VERSION "pitwall.dbc 3.0 — AIM MXP SmartyCam Enhanced CAN Protocol (CANable 2.0 → Pixel 10)"

NS_ :

BS_:

BU_: DASH AIM ECU IMU GPS TPMS

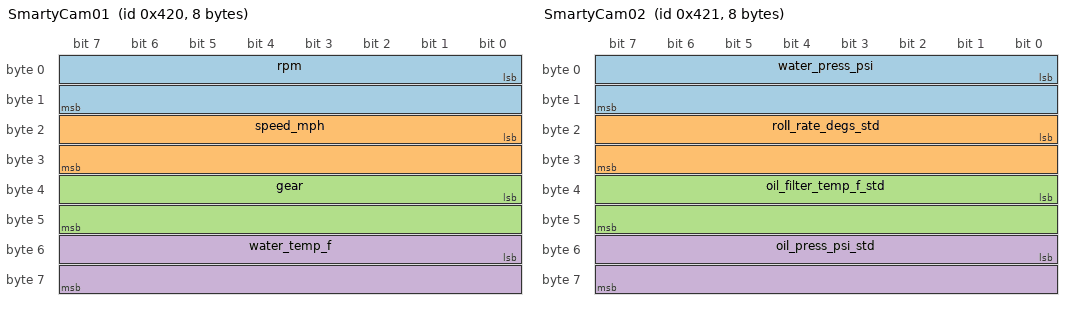
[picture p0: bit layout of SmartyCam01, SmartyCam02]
BO_ 1056 SmartyCam01: 8 AIM
 SG_ rpm : 0|16@1+ (1,0) [0|20000] "rpm" DASH
 SG_ speed_mph : 16|16@1+ (0.1,0) [0|650] "mph" DASH
 SG_ gear : 32|16@1+ (1,0) [-1|8] "gear" DASH
 SG_ water_temp_f : 48|16@1+ (0.1,0) [0|300] "F" DASH

BO_ 1057 SmartyCam02: 8 AIM
 SG_ water_press_psi : 0|16@1+ (0.1,0) [0|100] "psi" DASH
 SG_ roll_rate_degs_std : 16|16@1- (0.1,0) [-3276|3276] "deg/s" DASH
 SG_ oil_filter_temp_f_std : 32|16@1+ (0.1,0) [0|400] "F" DASH
 SG_ oil_press_psi_std : 48|16@1+ (0.1,0) [0|200] "psi" DASH

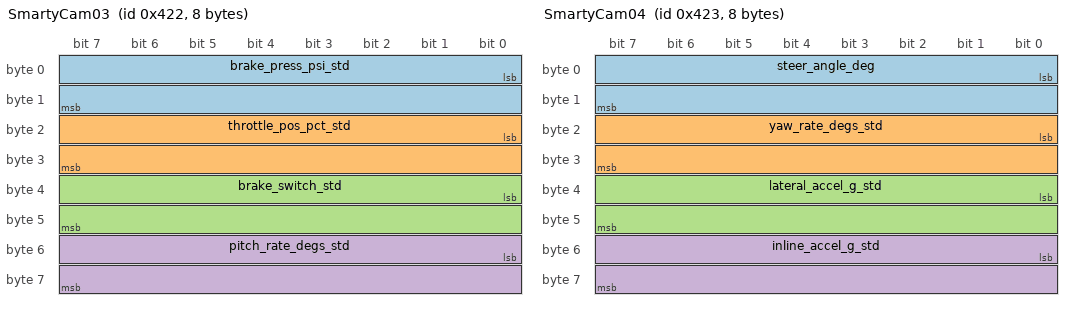
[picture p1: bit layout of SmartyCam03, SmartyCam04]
BO_ 1058 SmartyCam03: 8 AIM
 SG_ brake_press_psi_std : 0|16@1+ (1,0) [0|2000] "psi" DASH
 SG_ throttle_pos_pct_std : 16|16@1+ (0.01,0) [0|100] "%" DASH
 SG_ brake_switch_std : 32|16@1+ (1,0) [0|1] "binary" DASH
 SG_ pitch_rate_degs_std : 48|16@1- (0.1,0) [-3276|3276] "deg/s" DASH

BO_ 1059 SmartyCam04: 8 AIM
 SG_ steer_angle_deg : 0|16@1- (0.1,0) [-3276|3276] "deg" DASH
 SG_ yaw_rate_degs_std : 16|16@1- (0.1,0) [-3276|3276] "deg/s" DASH
 SG_ lateral_accel_g_std : 32|16@1- (0.01,0) [-32|32] "g" DASH
 SG_ inline_accel_g_std : 48|16@1- (0.01,0) [-32|32] "g" DASH

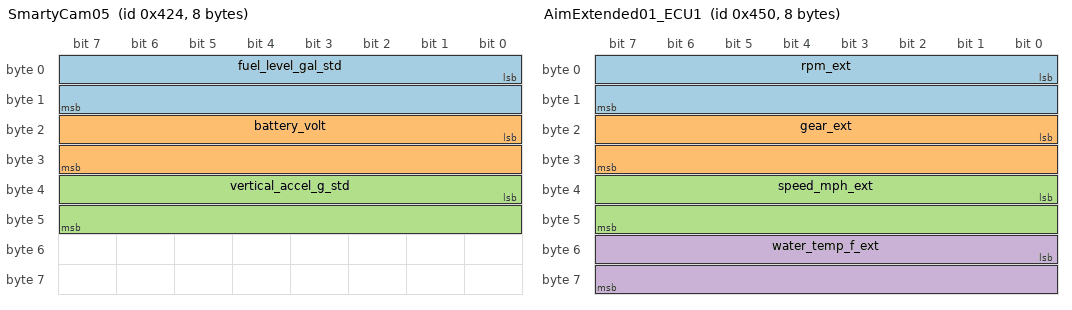
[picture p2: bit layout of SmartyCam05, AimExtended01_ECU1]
BO_ 1060 SmartyCam05: 8 AIM
 SG_ fuel_level_gal_std : 0|16@1+ (0.01,0) [0|100] "gal" DASH
 SG_ battery_volt : 16|16@1+ (0.1,0) [0|30] "V" DASH
 SG_ vertical_accel_g_std : 32|16@1- (0.01,0) [-32|32] "g" DASH

BO_ 1104 AimExtended01_ECU1: 8 AIM
 SG_ rpm_ext : 0|16@1+ (1,0) [0|20000] "rpm" DASH
 SG_ gear_ext : 16|16@1+ (1,0) [-1|8] "gear" DASH
 SG_ speed_mph_ext : 32|16@1+ (0.1,0) [0|650] "mph" DASH
 SG_ water_temp_f_ext : 48|16@1+ (0.1,0) [0|300] "F" DASH

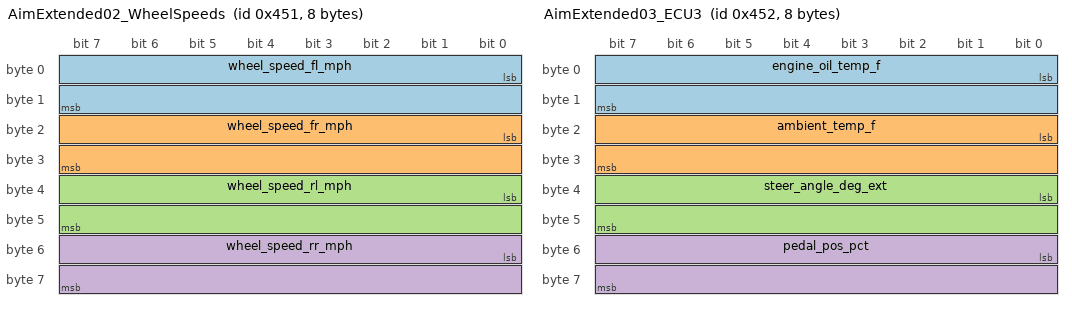
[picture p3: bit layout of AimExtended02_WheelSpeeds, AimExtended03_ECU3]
BO_ 1105 AimExtended02_WheelSpeeds: 8 AIM
 SG_ wheel_speed_fl_mph : 0|16@1+ (0.1,0) [0|650] "mph" DASH
 SG_ wheel_speed_fr_mph : 16|16@1+ (0.1,0) [0|650] "mph" DASH
 SG_ wheel_speed_rl_mph : 32|16@1+ (0.1,0) [0|650] "mph" DASH
 SG_ wheel_speed_rr_mph : 48|16@1+ (0.1,0) [0|650] "mph" DASH

BO_ 1106 AimExtended03_ECU3: 8 AIM
 SG_ engine_oil_temp_f : 0|16@1+ (0.1,0) [0|400] "F" DASH
 SG_ ambient_temp_f : 16|16@1+ (0.1,0) [-40|200] "F" DASH
 SG_ steer_angle_deg_ext : 32|16@1- (0.1,0) [-3276|3276] "deg" DASH
 SG_ pedal_pos_pct : 48|16@1+ (0.01,0) [0|100] "%" DASH

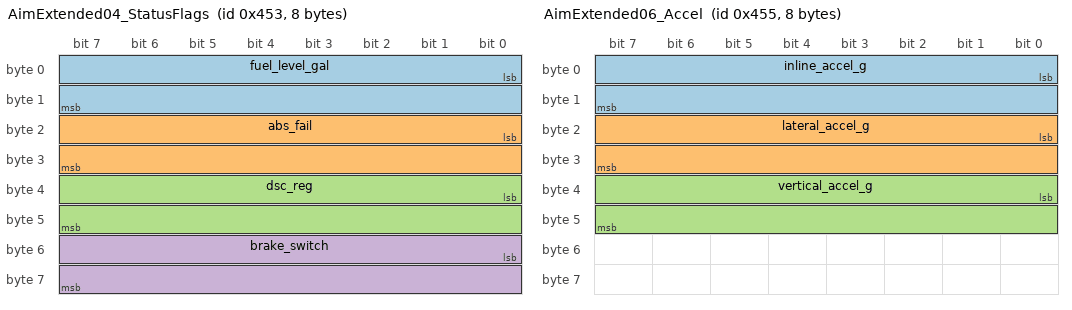
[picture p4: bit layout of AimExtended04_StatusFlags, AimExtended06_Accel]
BO_ 1107 AimExtended04_StatusFlags: 8 AIM
 SG_ fuel_level_gal : 0|16@1+ (0.01,0) [0|100] "gal" DASH
 SG_ abs_fail : 16|16@1+ (1,0) [0|1] "binary" DASH
 SG_ dsc_reg : 32|16@1+ (1,0) [0|1] "binary" DASH
 SG_ brake_switch : 48|16@1+ (1,0) [0|1] "binary" DASH

BO_ 1108 AimExtended05_MIL: 8 AIM
 SG_ mil_chk_eng : 0|16@1+ (1,0) [0|65535] "bitfield" DASH

BO_ 1109 AimExtended06_Accel: 8 AIM
 SG_ inline_accel_g : 0|16@1- (0.01,0) [-32|32] "g" DASH
 SG_ lateral_accel_g : 16|16@1- (0.01,0) [-32|32] "g" DASH
 SG_ vertical_accel_g : 32|16@1- (0.01,0) [-32|32] "g" DASH

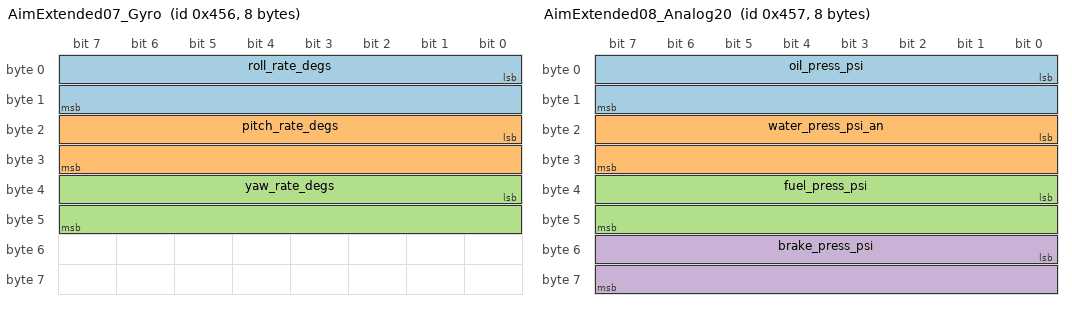
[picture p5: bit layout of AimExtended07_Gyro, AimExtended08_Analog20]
BO_ 1110 AimExtended07_Gyro: 8 AIM
 SG_ roll_rate_degs : 0|16@1- (0.1,0) [-3276|3276] "deg/s" DASH
 SG_ pitch_rate_degs : 16|16@1- (0.1,0) [-3276|3276] "deg/s" DASH
 SG_ yaw_rate_degs : 32|16@1- (0.1,0) [-3276|3276] "deg/s" DASH

BO_ 1111 AimExtended08_Analog20: 8 AIM
 SG_ oil_press_psi : 0|16@1+ (0.1,0) [0|200] "psi" DASH
 SG_ water_press_psi_an : 16|16@1+ (0.1,0) [0|100] "psi" DASH
 SG_ fuel_press_psi : 32|16@1+ (0.1,0) [0|200] "psi" DASH
 SG_ brake_press_psi : 48|16@1+ (1,0) [0|2000] "psi" DASH

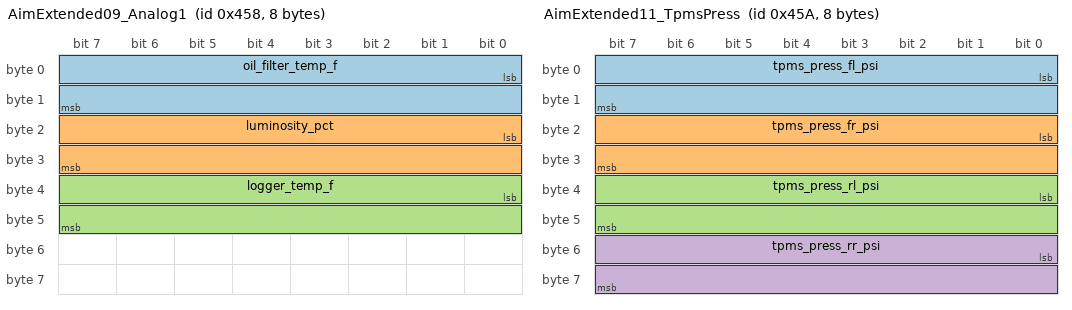
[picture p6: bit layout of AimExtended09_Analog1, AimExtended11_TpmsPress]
BO_ 1112 AimExtended09_Analog1: 8 AIM
 SG_ oil_filter_temp_f : 0|16@1+ (0.1,0) [0|400] "F" DASH
 SG_ luminosity_pct : 16|16@1+ (1,0) [0|100] "%" DASH
 SG_ logger_temp_f : 32|16@1+ (0.1,0) [-40|200] "F" DASH

BO_ 1113 AimExtended10_GPS: 8 AIM
 SG_ gps_lat : 0|32@1- (1e-7,0) [-90|90] "deg" DASH
 SG_ gps_lon : 32|32@1- (1e-7,0) [-180|180] "deg" DASH

BO_ 1114 AimExtended11_TpmsPress: 8 AIM
 SG_ tpms_press_fl_psi : 0|16@1+ (0.1,0) [0|100] "psi" DASH
 SG_ tpms_press_fr_psi : 16|16@1+ (0.1,0) [0|100] "psi" DASH
 SG_ tpms_press_rl_psi : 32|16@1+ (0.1,0) [0|100] "psi" DASH
 SG_ tpms_press_rr_psi : 48|16@1+ (0.1,0) [0|100] "psi" DASH

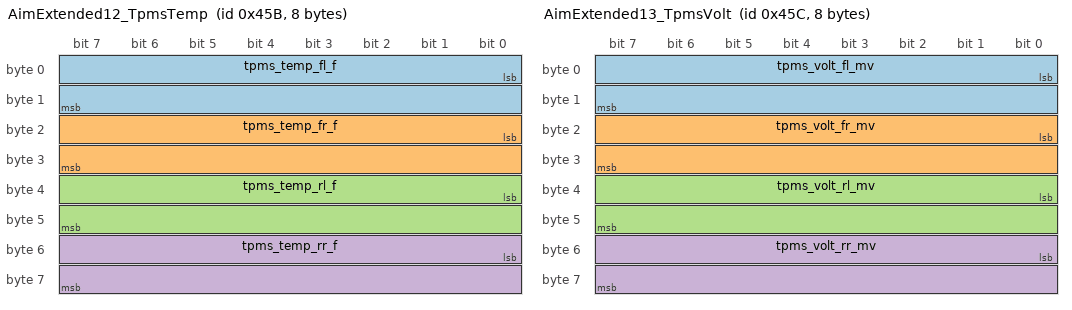
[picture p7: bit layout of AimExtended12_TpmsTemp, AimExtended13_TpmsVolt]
BO_ 1115 AimExtended12_TpmsTemp: 8 AIM
 SG_ tpms_temp_fl_f : 0|16@1+ (0.1,0) [-40|400] "F" DASH
 SG_ tpms_temp_fr_f : 16|16@1+ (0.1,0) [-40|400] "F" DASH
 SG_ tpms_temp_rl_f : 32|16@1+ (0.1,0) [-40|400] "F" DASH
 SG_ tpms_temp_rr_f : 48|16@1+ (0.1,0) [-40|400] "F" DASH

BO_ 1116 AimExtended13_TpmsVolt: 8 AIM
 SG_ tpms_volt_fl_mv : 0|16@1+ (1,0) [0|5000] "mV" DASH
 SG_ tpms_volt_fr_mv : 16|16@1+ (1,0) [0|5000] "mV" DASH
 SG_ tpms_volt_rl_mv : 32|16@1+ (1,0) [0|5000] "mV" DASH
 SG_ tpms_volt_rr_mv : 48|16@1+ (1,0) [0|5000] "mV" DASH

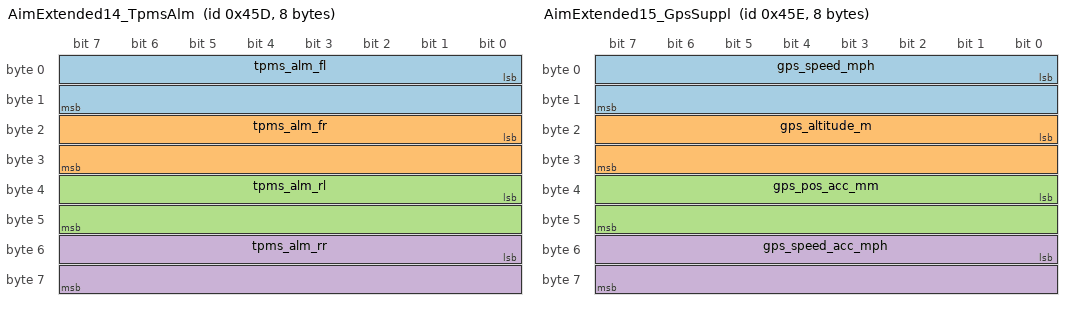
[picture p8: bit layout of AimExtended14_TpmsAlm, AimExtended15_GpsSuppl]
BO_ 1117 AimExtended14_TpmsAlm: 8 AIM
 SG_ tpms_alm_fl : 0|16@1+ (1,0) [0|65535] "bitfield" DASH
 SG_ tpms_alm_fr : 16|16@1+ (1,0) [0|65535] "bitfield" DASH
 SG_ tpms_alm_rl : 32|16@1+ (1,0) [0|65535] "bitfield" DASH
 SG_ tpms_alm_rr : 48|16@1+ (1,0) [0|65535] "bitfield" DASH

BO_ 1118 AimExtended15_GpsSuppl: 8 AIM
 SG_ gps_speed_mph : 0|16@1+ (0.1,0) [0|650] "mph" DASH
 SG_ gps_altitude_m : 16|16@1+ (1,0) [-1000|10000] "m" DASH
 SG_ gps_pos_acc_mm : 32|16@1+ (1,0) [0|65535] "mm" DASH
 SG_ gps_speed_acc_mph : 48|16@1+ (0.1,0) [0|650] "mph" DASH

CM_ "AIM MXP SmartyCam Enhanced CAN Protocol v3.0 — superset matching PDF v3.0";
CM_ BO_ 1056 "0x420 — Standard SmartyCam Message 1: RPM, GPS Speed, Gear, Water Temp (10 Hz nominal, 16 Hz observed)";
CM_ BO_ 1057 "0x421 — Standard SmartyCam Message 2: Water Press, Roll Rate slot, Oil Filter Temp slot, Oil Press slot (50 Hz nominal; IMU slot returns 0xCFFE padding)";
CM_ BO_ 1058 "0x422 — Standard SmartyCam Message 3: Brake Press slot, Pedal Pos slot, Brake Switch slot, Pitch Rate slot (50 Hz nominal; IMU slot returns 0xCFFE padding)";
CM_ BO_ 1059 "0x423 — Standard SmartyCam Message 4: Steer Angle, Yaw Rate slot, Lateral Accel slot, Inline Accel slot (50 Hz nominal; IMU slot returns 0xCFFE padding)";
CM_ BO_ 1060 "0x424 — Standard SmartyCam Message 5: Fuel slot, Battery, Vertical Accel slot (50 Hz nominal; vertical-accel slot returns 0xCFFE padding)";
CM_ BO_ 1104 "0x450 — Extended ECU Block 1: RPM, Gear, Speed, Water Temp (10 Hz; AUTHORITATIVE)";
CM_ BO_ 1105 "0x451 — Extended Wheel Speeds FL/FR/RL/RR (10 Hz; from BMW DSC)";
CM_ BO_ 1106 "0x452 — Extended ECU Block 3: Engine Oil Temp, Outside Temp, Steer Angle, Pedal Position (10 Hz)";
CM_ BO_ 1107 "0x453 — Extended ECU Block 4: Fuel, ABS Fail, DSC Reg, Brake Switch (10 Hz)";
CM_ BO_ 1108 "0x454 — Extended ECU Block 5: MIL CHK ENG + 3 reserved (10 Hz)";
CM_ BO_ 1109 "0x455 — Extended Accelerometers — Inline/Lateral/Vertical (50 Hz; AUTHORITATIVE)";
CM_ BO_ 1110 "0x456 — Extended Gyroscopes — Roll/Pitch/Yaw rate (50 Hz; AUTHORITATIVE)";
CM_ BO_ 1111 "0x457 — AIM Analog Sensors 20 Hz: Oil P, Water P, Fuel P, Brake P (20 Hz)";
CM_ BO_ 1112 "0x458 — AIM Analog Sensors 1 Hz: Oil Filter Temp (PT-100), Luminosity, Logger Temp (1 Hz)";
CM_ BO_ 1113 "0x459 — GPS Latitude/Longitude (signed int32 deg7 format, 20 Hz, ~1.1 cm res)";
CM_ BO_ 1114 "0x45A — TPMS Tire Pressures FL/FR/RL/RR (10 Hz, TrailBrake v1)";
CM_ BO_ 1115 "0x45B — TPMS Tire Temperatures FL/FR/RL/RR (10 Hz, TrailBrake v1)";
CM_ BO_ 1116 "0x45C — TPMS Sensor Voltages FL/FR/RL/RR (10 Hz, TrailBrake v1)";
CM_ BO_ 1117 "0x45D — TPMS Alarm Status FL/FR/RL/RR (1 Hz hardware limit, TrailBrake v1)";
CM_ BO_ 1118 "0x45E — GPS Supplemental: Speed, Altitude, Pos Accuracy, Speed Accuracy (20 Hz)";

CM_ SG_ 1057 roll_rate_degs_std "Standard-stream slot — 0xCFFE padding observed. Prefer 0x456 roll_rate_degs.";
CM_ SG_ 1057 oil_filter_temp_f_std "Standard-stream slot — prefer 0x458 oil_filter_temp_f.";
CM_ SG_ 1057 oil_press_psi_std "Standard-stream slot — prefer 0x457 oil_press_psi.";
CM_ SG_ 1058 brake_press_psi_std "Standard-stream slot — prefer 0x457 brake_press_psi.";
CM_ SG_ 1058 throttle_pos_pct_std "Standard-stream slot — prefer 0x452 pedal_pos_pct (same source).";
CM_ SG_ 1058 brake_switch_std "Standard-stream slot — prefer 0x453 brake_switch.";
CM_ SG_ 1058 pitch_rate_degs_std "Standard-stream slot — 0xCFFE padding observed. Prefer 0x456 pitch_rate_degs.";
CM_ SG_ 1059 yaw_rate_degs_std "Standard-stream slot — 0xCFFE padding observed. Prefer 0x456 yaw_rate_degs.";
CM_ SG_ 1059 lateral_accel_g_std "Standard-stream slot — 0xCFFE padding observed. Prefer 0x455 lateral_accel_g.";
CM_ SG_ 1059 inline_accel_g_std "Standard-stream slot — 0xCFFE padding observed. Prefer 0x455 inline_accel_g.";
CM_ SG_ 1060 fuel_level_gal_std "Standard-stream slot — prefer 0x453 fuel_level_gal.";
CM_ SG_ 1060 vertical_accel_g_std "Standard-stream slot — 0xCFFE padding observed. Prefer 0x455 vertical_accel_g.";
CM_ SG_ 1056 gear "Always 0 (or 0xCFFE) on MSS54HP — derive from rpm/wheel-speed ratio. PDF §12.";
CM_ SG_ 1104 gear_ext "Always 0 (or 0xCFFE) on MSS54HP — derive from rpm/wheel-speed ratio. PDF §12.";
CM_ SG_ 1106 engine_oil_temp_f "DME sump sensor — lags real oil temp. Primary oil health = oil_filter_temp_f (0x458).";
CM_ SG_ 1111 oil_press_psi "Analog sensor — authoritative; 0xFFFF sentinel = no reading.";
CM_ SG_ 1112 oil_filter_temp_f "PT-100 at filter housing — slow thermal response, not for transients.";
CM_ SG_ 1113 gps_lat "Decimal degrees x 1e7. Signed int32_le. Negative = South hemisphere.";
CM_ SG_ 1113 gps_lon "Decimal degrees x 1e7. Signed int32_le. Negative = West hemisphere (e.g. California approx -122).";
CM_ SG_ 1118 gps_altitude_m "65535 = sentinel (no GPS altitude fix).";
CM_ SG_ 1118 gps_pos_acc_mm "uBlox GPS reported horizontal position accuracy estimate.";
CM_ SG_ 1117 tpms_alm_fl "Bitfield: 0x01=air leak, 0x10=low temp, 0x20=sensor fail. 0 = no alarm.";
